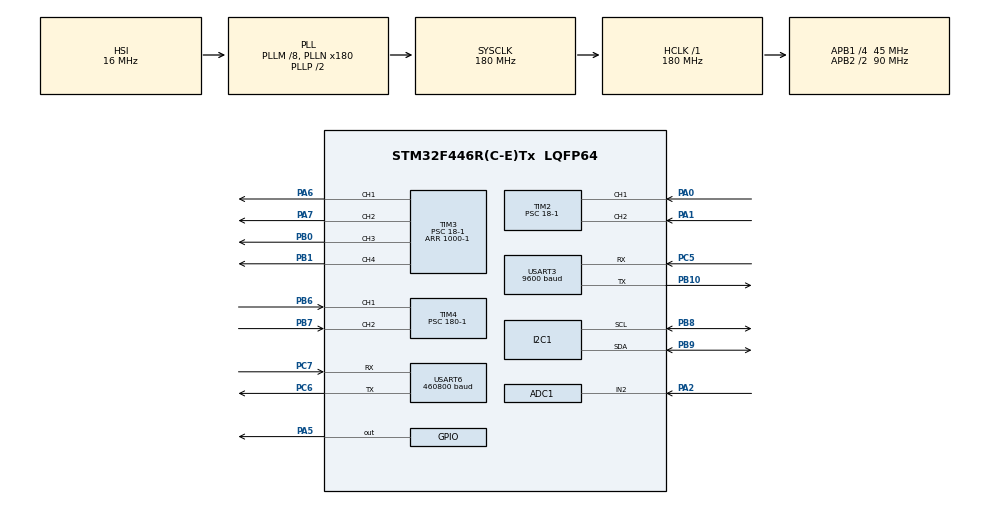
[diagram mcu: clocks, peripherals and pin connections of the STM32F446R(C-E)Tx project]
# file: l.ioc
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ADC1.Channel-0\#ChannelRegularConversion=ADC_CHANNEL_2
ADC1.NbrOfConversionFlag=1
ADC1.Rank-0\#ChannelRegularConversion=1
ADC1.SamplingTime-0\#ChannelRegularConversion=ADC_SAMPLETIME_3CYCLES
ADC1.master=1
Dma.Request0=USART3_TX
Dma.Request1=USART3_RX
Dma.USART3_RX.1.Direction=DMA_PERIPH_TO_MEMORY
Dma.USART3_RX.1.FIFOMode=DMA_FIFOMODE_DISABLE
Dma.USART3_RX.1.Instance=DMA1_Stream1
Dma.USART3_RX.1.MemDataAlignment=DMA_MDATAALIGN_BYTE
Dma.USART3_RX.1.MemInc=DMA_MINC_ENABLE
Dma.USART3_RX.1.Mode=DMA_NORMAL
Dma.USART3_RX.1.PeriphDataAlignment=DMA_PDATAALIGN_BYTE
Dma.USART3_RX.1.PeriphInc=DMA_PINC_DISABLE
Dma.USART3_RX.1.Priority=DMA_PRIORITY_LOW
Dma.USART3_TX.0.Direction=DMA_MEMORY_TO_PERIPH
Dma.USART3_TX.0.FIFOMode=DMA_FIFOMODE_DISABLE
Dma.USART3_TX.0.Instance=DMA1_Stream3
Dma.USART3_TX.0.MemDataAlignment=DMA_MDATAALIGN_BYTE
Dma.USART3_TX.0.MemInc=DMA_MINC_ENABLE
Dma.USART3_TX.0.Mode=DMA_NORMAL
Dma.USART3_TX.0.PeriphDataAlignment=DMA_PDATAALIGN_BYTE
Dma.USART3_TX.0.PeriphInc=DMA_PINC_DISABLE
Dma.USART3_TX.0.Priority=DMA_PRIORITY_LOW
Mcu.Family=STM32F4
Mcu.Name=STM32F446R(C-E)Tx
Mcu.Package=LQFP64
NVIC.DMA1_Stream1_IRQn=true\:0\:0\:false\:false\:true\:false\:true\:true
NVIC.DMA1_Stream3_IRQn=true\:0\:0\:false\:false\:true\:false\:true\:true
NVIC.PriorityGroup=NVIC_PRIORITYGROUP_4
NVIC.USART3_IRQn=true\:0\:0\:false\:false\:true\:true\:true\:true
NVIC.USART6_IRQn=true\:0\:0\:false\:false\:true\:true\:true\:true
PA0-WKUP.Signal=S_TIM2_CH1_ETR
PA1.Signal=S_TIM2_CH2
PA13.Mode=Serial_Wire
PA13.Signal=SYS_JTMS-SWDIO
PA14.Mode=Serial_Wire
PA14.Signal=SYS_JTCK-SWCLK
PA2.Signal=ADCx_IN2
PA5.Signal=GPIO_Output
PA6.Signal=S_TIM3_CH1
PA7.Signal=S_TIM3_CH2
PB0.Signal=S_TIM3_CH3
PB1.Signal=S_TIM3_CH4
PB10.Mode=Asynchronous
PB10.Signal=USART3_TX
PB6.Signal=S_TIM4_CH1
PB7.Signal=S_TIM4_CH2
PB8.GPIO_Pu=GPIO_PULLUP
PB8.Mode=I2C
PB8.Signal=I2C1_SCL
PB9.GPIO_Pu=GPIO_PULLUP
PB9.Mode=I2C
PB9.Signal=I2C1_SDA
PC5.Mode=Asynchronous
PC5.Signal=USART3_RX
PC6.Mode=Asynchronous
PC6.Signal=USART6_TX
PC7.Mode=Asynchronous
PC7.Signal=USART6_RX
ProjectManager.HeapSize=0x200
ProjectManager.StackSize=0x400
ProjectManager.TargetToolchain=MDK-ARM V5.32
RCC.AHBFreq_Value=180000000
RCC.APB1CLKDivider=RCC_HCLK_DIV4
RCC.APB1Freq_Value=45000000
RCC.APB1TimFreq_Value=90000000
RCC.APB2CLKDivider=RCC_HCLK_DIV2
RCC.APB2Freq_Value=90000000
RCC.APB2TimFreq_Value=180000000
RCC.CortexFreq_Value=180000000
RCC.HCLKFreq_Value=180000000
RCC.PLLM=8
RCC.PLLN=180
RCC.SYSCLKFreq_VALUE=180000000
RCC.SYSCLKSource=RCC_SYSCLKSOURCE_PLLCLK
RCC.USBFreq_Value=180000000
RCC.VCOOutputFreq_Value=360000000
SH.ADCx_IN2.0=ADC1_IN2,IN2
SH.S_TIM2_CH1_ETR.0=TIM2_CH1,Encoder_Interface
SH.S_TIM2_CH2.0=TIM2_CH2,Encoder_Interface
SH.S_TIM3_CH1.0=TIM3_CH1,PWM Generation1 CH1
SH.S_TIM3_CH2.0=TIM3_CH2,PWM Generation2 CH2
SH.S_TIM3_CH3.0=TIM3_CH3,PWM Generation3 CH3
SH.S_TIM3_CH4.0=TIM3_CH4,PWM Generation4 CH4
SH.S_TIM4_CH1.0=TIM4_CH1,Encoder_Interface
SH.S_TIM4_CH2.0=TIM4_CH2,Encoder_Interface
TIM2.Prescaler=18-1
TIM3.Channel-PWM\ Generation1\ CH1=TIM_CHANNEL_1
TIM3.Channel-PWM\ Generation2\ CH2=TIM_CHANNEL_2
TIM3.Channel-PWM\ Generation3\ CH3=TIM_CHANNEL_3
TIM3.Channel-PWM\ Generation4\ CH4=TIM_CHANNEL_4
TIM3.Period=1000-1
TIM3.Prescaler=18-1
TIM4.Prescaler=180-1
USART3.BaudRate=9600
USART3.VirtualMode=VM_ASYNC
USART6.BaudRate=460800
USART6.VirtualMode=VM_ASYNC
board=custom

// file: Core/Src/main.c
/* USER CODE BEGIN Header */
/**
  ******************************************************************************
  * @file           : main.c
  * @brief          : Main program body
  ******************************************************************************
  * @attention
  *
  * Copyright (c) 2025 STMicroelectronics.
  * All rights reserved.
  *
  * This software is licensed under terms that can be found in the LICENSE file
  * in the root directory of this software component.
  * If no LICENSE file comes with this software, it is provided AS-IS.
  *
  ******************************************************************************
  */
/* USER CODE END Header */
#include "main.h"
#include "adc.h"
#include "dma.h"
#include "i2c.h"
#include "tim.h"
#include "usart.h"
#include "gpio.h"

/* USER CODE BEGIN Includes */
#include "imu.h"
#include "bluetooth.h"
#include "data.h"
#include "motor.h"
#include "rplidar.h"

int16_t gx = 0, gy = 0, gz = 0;
float yaw = 0;
float gyro_z_offset = 0;  // ????? 0

/* USER CODE END Includes */

void SystemClock_Config(void);

int main(void)
{

  /* MCU Configuration--------------------------------------------------------*/

  /* Reset of all peripherals, Initializes the Flash interface and the Systick. */
  HAL_Init();

  /* Configure the system clock */
  SystemClock_Config();

  /* Initialize all configured peripherals */
  MX_GPIO_Init();
  MX_DMA_Init();
  MX_TIM2_Init();
  MX_ADC1_Init();
  MX_TIM3_Init();
  MX_TIM4_Init();
  MX_USART3_UART_Init();
  MX_I2C1_Init();
  MX_USART6_UART_Init();
  /* USER CODE BEGIN 2 */

	uart_init();
	motor_init();  // ??PWM????????
	RPLIDAR_Init();  // ??? RPLIDAR ??????

  while (1)
  {

    /* USER CODE END WHILE */

  }
}

void SystemClock_Config(void)
{
  RCC_OscInitTypeDef RCC_OscInitStruct = {0};
  RCC_ClkInitTypeDef RCC_ClkInitStruct = {0};

  /** Configure the main internal regulator output voltage
  */
  __HAL_RCC_PWR_CLK_ENABLE();
  __HAL_PWR_VOLTAGESCALING_CONFIG(PWR_REGULATOR_VOLTAGE_SCALE1);

  /** Initializes the RCC Oscillators according to the specified parameters
  * in the RCC_OscInitTypeDef structure.
  */
  RCC_OscInitStruct.OscillatorType = RCC_OSCILLATORTYPE_HSI;
  RCC_OscInitStruct.HSIState = RCC_HSI_ON;
  RCC_OscInitStruct.HSICalibrationValue = RCC_HSICALIBRATION_DEFAULT;
  RCC_OscInitStruct.PLL.PLLState = RCC_PLL_ON;
  RCC_OscInitStruct.PLL.PLLSource = RCC_PLLSOURCE_HSI;
  RCC_OscInitStruct.PLL.PLLM = 8;
  RCC_OscInitStruct.PLL.PLLN = 180;
  RCC_OscInitStruct.PLL.PLLP = RCC_PLLP_DIV2;
  RCC_OscInitStruct.PLL.PLLQ = 2;
  RCC_OscInitStruct.PLL.PLLR = 2;
  if (HAL_RCC_OscConfig(&RCC_OscInitStruct) != HAL_OK)
  {
    Error_Handler();
  }

  /** Activate the Over-Drive mode
  */
  if (HAL_PWREx_EnableOverDrive() != HAL_OK)
  {
    Error_Handler();
  }

  /** Initializes the CPU, AHB and APB buses clocks
  */
  RCC_ClkInitStruct.ClockType = RCC_CLOCKTYPE_HCLK|RCC_CLOCKTYPE_SYSCLK
                              |RCC_CLOCKTYPE_PCLK1|RCC_CLOCKTYPE_PCLK2;
  RCC_ClkInitStruct.SYSCLKSource = RCC_SYSCLKSOURCE_PLLCLK;
  RCC_ClkInitStruct.AHBCLKDivider = RCC_SYSCLK_DIV1;
  RCC_ClkInitStruct.APB1CLKDivider = RCC_HCLK_DIV4;
  RCC_ClkInitStruct.APB2CLKDivider = RCC_HCLK_DIV2;

  if (HAL_RCC_ClockConfig(&RCC_ClkInitStruct, FLASH_LATENCY_5) != HAL_OK)
  {
    Error_Handler();
  }
}

void Error_Handler(void)
{
  __disable_irq();
  while (1)
  {
  }
}
